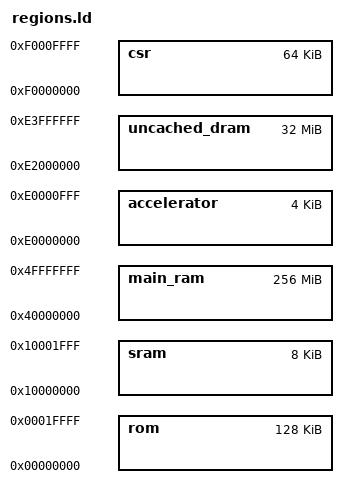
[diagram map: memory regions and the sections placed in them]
MEMORY {
	rom : ORIGIN = 0x00000000, LENGTH = 0x00020000
	sram : ORIGIN = 0x10000000, LENGTH = 0x00002000
	main_ram : ORIGIN = 0x40000000, LENGTH = 0x10000000
	uncached_dram : ORIGIN = 0xe2000000, LENGTH = 0x02000000
	accelerator : ORIGIN = 0xe0000000, LENGTH = 0x00001000
	csr : ORIGIN = 0xf0000000, LENGTH = 0x00010000
}
